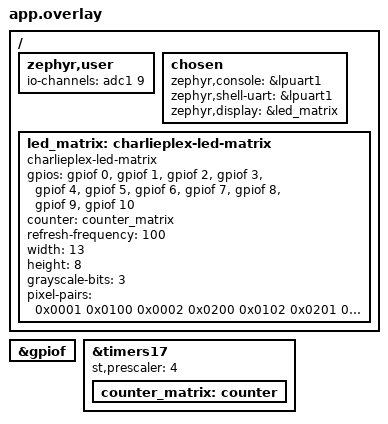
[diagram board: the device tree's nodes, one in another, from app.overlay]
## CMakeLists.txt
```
# Copyright (c) 2026 Eoin Jordan
# SPDX-License-Identifier: Apache-2.0
#
# ExecuTorch anomaly classifier on the Arduino UNO Q's STM32U585 (Cortex-M33)
# under Zephyr. Same structure as the upstream zephyr/samples/hello-executorch
# sample: model embedded as a const array, only the operators in the .pte are
# linked.

cmake_minimum_required(VERSION 3.24)

set(CMAKE_SKIP_INSTALL_RULES ON CACHE BOOL "" FORCE)

set(ET_PTE_FILE_PATH
    "${CMAKE_CURRENT_SOURCE_DIR}/model/anomaly_net.pte"
    CACHE FILEPATH "Path to the ExecuTorch .pte model to embed"
)
if(NOT IS_ABSOLUTE "${ET_PTE_FILE_PATH}")
  get_filename_component(
    ET_PTE_FILE_PATH "${ET_PTE_FILE_PATH}" ABSOLUTE BASE_DIR
    "${CMAKE_CURRENT_SOURCE_DIR}"
  )
endif()
if(NOT EXISTS "${ET_PTE_FILE_PATH}")
  message(FATAL_ERROR "Model not found at ET_PTE_FILE_PATH=${ET_PTE_FILE_PATH}. "
                      "Run train/train_anomaly.py first or pass -DET_PTE_FILE_PATH=<file>.")
endif()

# Bindings for the vendored LED matrix driver (dts/bindings/).
list(APPEND DTS_ROOT ${CMAKE_CURRENT_SOURCE_DIR})

find_package(Zephyr REQUIRED HINTS $ENV{ZEPHYR_BASE})
project(executorch_arduino_uno_q)

find_package(Python3 COMPONENTS Interpreter REQUIRED)

set(CMAKE_CXX_FLAGS
    "${CMAKE_CXX_FLAGS} -Wall -Wno-switch -Wno-float-conversion -ffunction-sections -fdata-sections"
)

if(NOT DEFINED EXECUTORCH_DIR)
  if(DEFINED ZEPHYR_EXECUTORCH_MODULE_DIR)
    set(EXECUTORCH_DIR ${ZEPHYR_EXECUTORCH_MODULE_DIR})
  else()
    message(FATAL_ERROR "ExecuTorch Zephyr module not found. Check west.yml and run west update.")
  endif()
endif()
message(STATUS "EXECUTORCH_DIR=${EXECUTORCH_DIR}")

include(${EXECUTORCH_DIR}/tools/cmake/Utils.cmake)
include(${EXECUTORCH_DIR}/backends/arm/cmake/ArmRunnerUtils.cmake)

if(NOT TARGET portable_kernels)
  set(EXECUTORCH_PORTABLE_BUILD_KERNELS_ONLY ON)
  add_subdirectory(
    ${EXECUTORCH_DIR}/kernels/portable
    ${CMAKE_CURRENT_BINARY_DIR}/executorch/kernels/portable
  )
  unset(EXECUTORCH_PORTABLE_BUILD_KERNELS_ONLY)
endif()

set(_selected_ops_libs)

arm_runner_create_selected_ops_lib(
  LIB_NAME "unoq_portable_ops_lib"
  FUNCTIONS_YAML "${EXECUTORCH_DIR}/kernels/portable/functions.yaml"
  OPS_FROM_MODEL "${ET_PTE_FILE_PATH}"
  KERNEL_LIBS portable_kernels
  DEPS executorch
  DTYPE_SELECTIVE_BUILD ""
)
list(APPEND _selected_ops_libs unoq_portable_ops_lib)

if(TARGET cortex_m_kernels)
  arm_runner_create_selected_ops_lib(
    LIB_NAME "unoq_cortex_m_ops_lib"
    CUSTOM_OPS_YAML "${EXECUTORCH_DIR}/backends/cortex_m/ops/operators.yaml"
    OPS_FROM_MODEL "${ET_PTE_FILE_PATH}"
    KERNEL_LIBS cortex_m_kernels
    DEPS executorch
  )
  list(APPEND _selected_ops_libs unoq_cortex_m_ops_lib)
endif()

set(_local_flatcc_root ${CMAKE_BINARY_DIR}/flatcc_src)
if(NOT EXISTS ${_local_flatcc_root}/CMakeLists.txt)
  file(MAKE_DIRECTORY ${_local_flatcc_root})
  execute_process(
    COMMAND ${CMAKE_COMMAND} -E copy_directory
            ${EXECUTORCH_DIR}/third-party/flatcc ${_local_flatcc_root}
  )
endif()
set(EXECUTORCH_FLATCC_SOURCE_ROOT ${_local_flatcc_root} CACHE PATH "" FORCE)
set(EXECUTORCH_FLATCC_INSTALL_ROOT ${_local_flatcc_root} CACHE PATH "" FORCE)

set(_model_pte_header ${CMAKE_CURRENT_BINARY_DIR}/model_pte.h)
add_custom_command(
  OUTPUT ${_model_pte_header}
  COMMAND ${Python3_EXECUTABLE} ${CMAKE_CURRENT_SOURCE_DIR}/scripts/pte_to_header.py
          --pte ${ET_PTE_FILE_PATH} --out ${_model_pte_header}
  DEPENDS ${ET_PTE_FILE_PATH} ${CMAKE_CURRENT_SOURCE_DIR}/scripts/pte_to_header.py
  COMMENT "Converting ${ET_PTE_FILE_PATH} to model_pte.h"
)
add_custom_target(gen_model_header DEPENDS ${_model_pte_header})
add_dependencies(app gen_model_header)

# The ExecuTorch module's runtime includes <zephyr/kernel.h>, which needs
# Zephyr's generated headers. Order it explicitly so a parallel build does not
# compile it before they exist.
if(TARGET zephyr_generated_headers)
  foreach(_t executorch_core executorch portable_kernels kernels_util_all_deps cortex_m_kernels)
    if(TARGET ${_t})
      add_dependencies(${_t} zephyr_generated_headers)
    endif()
  endforeach()
endif()

target_sources(app PRIVATE src/main.cpp src/sensor.c)

if(CONFIG_APP_LED_MATRIX)
  target_sources(app PRIVATE src/matrix.c drivers/display_charlieplex_led_matrix.c)
endif()

target_compile_definitions(
  app PRIVATE
  APP_METHOD_ALLOCATOR_POOL_SIZE=${CONFIG_EXECUTORCH_METHOD_ALLOCATOR_POOL_SIZE}
  APP_TEMP_ALLOCATOR_POOL_SIZE=${CONFIG_EXECUTORCH_TEMP_ALLOCATOR_POOL_SIZE}
)

target_link_libraries(app PRIVATE libexecutorch ${_selected_ops_libs})
target_include_directories(app PRIVATE src ${CMAKE_CURRENT_BINARY_DIR})
```

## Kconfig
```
# Copyright (c) 2026 Eoin Jordan
# SPDX-License-Identifier: Apache-2.0

source "Kconfig.zephyr"

menu "ExecuTorch Arduino UNO Q anomaly sample"

config EXECUTORCH_METHOD_ALLOCATOR_POOL_SIZE
	int "Method allocator pool size in bytes"
	default 65536
	depends on EXECUTORCH

config EXECUTORCH_TEMP_ALLOCATOR_POOL_SIZE
	int "Temporary allocator pool size in bytes"
	default 8192
	depends on EXECUTORCH

config APP_SIM_SENSOR
	bool "Simulate the temperature sensor instead of reading A0"
	default y
	help
	  Generates a normal heater cycle in software and injects a spike
	  every 30 s so the Linux side sees both classes. Set to n once a
	  sensor is wired to A0.

config APP_SAMPLE_PERIOD_MS
	int "Sensor sample period in milliseconds"
	default 100
	help
	  Must match SAMPLE_HZ in train/model.py (10 Hz).

config APP_INFER_PERIOD_MS
	int "Inference period in milliseconds"
	default 500

config APP_MV_PER_DEGREE
	int "Sensor scale: millivolts per degree C (x10)"
	default 100
	help
	  Tenths of a millivolt per degree. Default 100 = 10.0 mV/C (TMP36).

config APP_MV_OFFSET
	int "Sensor offset: millivolts at 0 C"
	default 500
	help
	  TMP36 outputs 500 mV at 0 C.

config APP_ANOMALY_THRESHOLD_PERCENT
	int "Anomaly probability (percent) that lights the red LED"
	default 80

endmenu

config APP_LED_MATRIX
	bool "Show the anomaly probability on the 13x8 LED matrix"
	default y
	select GPIO
	select COUNTER
	select DISPLAY
	help
	  Rolling bar chart on the UNO Q's charlieplexed LED matrix: one column
	  per inference, height = p(anomaly), bright when the MCU flagged an
	  anomaly, dotted when the sensor reads out of range. The matrix driver
	  lives in firmware/drivers/ and is wired up in app.overlay.
```

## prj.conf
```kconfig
# Copyright (c) 2026 Eoin Jordan
# SPDX-License-Identifier: Apache-2.0

# ExecuTorch runtime, selective operator build
CONFIG_EXECUTORCH=y
CONFIG_EXECUTORCH_BUILD_PORTABLE_OPS=n
CONFIG_EXECUTORCH_ENABLE_LOGGING=y

# C++17 with full libstdc++
CONFIG_CPP=y
CONFIG_STD_CPP17=y

CONFIG_MAIN_STACK_SIZE=16384
CONFIG_HEAP_MEM_POOL_SIZE=32768

# Cortex-M33 FPU, hard-float ABI
CONFIG_FPU=y
CONFIG_FP_HARDABI=y

CONFIG_REQUIRES_FLOAT_PRINTF=y
CONFIG_PRINTK=y

# A0 on ADC1, RGB LEDs on GPIO
CONFIG_GPIO=y
CONFIG_ADC=y

CONFIG_EXECUTORCH_METHOD_ALLOCATOR_POOL_SIZE=65536
CONFIG_EXECUTORCH_TEMP_ALLOCATOR_POOL_SIZE=8192
```

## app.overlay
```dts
/* Copyright (c) 2026 Eoin Jordan
 * SPDX-License-Identifier: Apache-2.0
 *
 * A0 on the UNO Q header is PA4 = ADC1 channel 9 (14-bit, 3.3 V reference).
 * Expose it to the application as io-channels index 0.
 */

/ {
	zephyr,user {
		io-channels = <&adc1 9>;
	};
};

/* The board file puts the console on USART1, which is the header serial
 * (D0/D1). The UART that links the STM32 to the QRB2210 is LPUART1
 * (/dev/ttyHS1 on the Linux side), so send the console and the JSON stream
 * there instead.
 */
/ {
	chosen {
		zephyr,console = &lpuart1;
		zephyr,shell-uart = &lpuart1;
	};
};

/* 13x8 LED matrix: 11 charlieplexed lines on PF0..PF10, scanned from TIM17.
 * Node copied from upstream Zephyr main (boards/arduino/uno_q); the matching
 * driver is vendored in drivers/ until the manifest moves past v4.4.0.
 * pixel-pairs is row-major (index = y * 13 + x), entry = (high << 8) | low.
 */
/ {
	chosen {
		zephyr,display = &led_matrix;
	};

	led_matrix: charlieplex-led-matrix {
		compatible = "charlieplex-led-matrix";
		gpios = <&gpiof 0 0>, <&gpiof 1 0>, <&gpiof 2 0>,
			<&gpiof 3 0>, <&gpiof 4 0>, <&gpiof 5 0>,
			<&gpiof 6 0>, <&gpiof 7 0>, <&gpiof 8 0>,
			<&gpiof 9 0>, <&gpiof 10 0>;
		counter = <&counter_matrix>;
		refresh-frequency = <100>;
		width = <13>;
		height = <8>;
		grayscale-bits = <3>;
		pixel-pairs = <0x0001 0x0100 0x0002 0x0200 0x0102 0x0201 0x0003 0x0300 0x0103 0x0301
			       0x0203 0x0302 0x0004 0x0400 0x0104 0x0401 0x0204 0x0402 0x0304 0x0403
			       0x0005 0x0500 0x0105 0x0501 0x0205 0x0502 0x0305 0x0503 0x0405 0x0504
			       0x0006 0x0600 0x0106 0x0601 0x0206 0x0602 0x0306 0x0603 0x0406 0x0604
			       0x0506 0x0605 0x0007 0x0700 0x0107 0x0701 0x0207 0x0702 0x0307 0x0703
			       0x0407 0x0704 0x0507 0x0705 0x0607 0x0706 0x0008 0x0800 0x0108 0x0801
			       0x0208 0x0802 0x0308 0x0803 0x0408 0x0804 0x0508 0x0805 0x0608 0x0806
			       0x0708 0x0807 0x0009 0x0900 0x0109 0x0901 0x0209 0x0902 0x0309 0x0903
			       0x0409 0x0904 0x0509 0x0905 0x0609 0x0906 0x0709 0x0907 0x0809 0x0908
			       0x000a 0x0a00 0x010a 0x0a01 0x020a 0x0a02 0x030a 0x0a03 0x040a 0x0a04
			       0x050a 0x0a05 0x060a 0x0a06>;
	};
};

&gpiof {
	status = "okay";
};

&timers17 {
	status = "okay";
	st,prescaler = <4>;

	counter_matrix: counter {
		status = "okay";
	};
};
```

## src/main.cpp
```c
/* Copyright (c) 2026 Eoin Jordan
 * SPDX-License-Identifier: Apache-2.0
 *
 * MCU brain of the Arduino UNO Q dual-brain sample.
 *
 *   A0 (or simulated) --10 Hz--> ring buffer of 32 samples
 *        --every 500 ms--> ExecuTorch AnomalyNet --> one JSON line on the UART
 *                                               --> RGB LED 3 green / red
 *
 * The Linux brain (QRB2210) reads the JSON lines; see linux/anomaly_bridge.py.
 */

#include <executorch/extension/data_loader/buffer_data_loader.h>
#include <executorch/runtime/core/memory_allocator.h>
#include <executorch/runtime/core/span.h>
#include <executorch/runtime/executor/memory_manager.h>
#include <executorch/runtime/executor/method.h>
#include <executorch/runtime/executor/program.h>
#include <executorch/runtime/platform/log.h>
#include <executorch/runtime/platform/runtime.h>

#include <zephyr/drivers/gpio.h>
#include <zephyr/kernel.h>
#include <zephyr/sys/printk.h>
#include <zephyr/version.h>

#include <cmath>
#include <cstdint>
#include <cstring>
#include <vector>

#include "model_pte.h"
#include "sensor.h"
#include "matrix.h"
#include "test_input.h"

using executorch::aten::Tensor;
using executorch::aten::TensorImpl;
using executorch::extension::BufferDataLoader;
using executorch::runtime::Error;
using executorch::runtime::EValue;
using executorch::runtime::HierarchicalAllocator;
using executorch::runtime::MemoryAllocator;
using executorch::runtime::MemoryManager;
using executorch::runtime::Method;
using executorch::runtime::MethodMeta;
using executorch::runtime::Program;
using executorch::runtime::Result;
using executorch::runtime::Span;
using executorch::runtime::TensorInfo;

static constexpr float kMean = 50.0f;
static constexpr float kScale = 20.0f;
static constexpr size_t kWindow = TEST_WINDOW;
static constexpr size_t kNumClasses = TEST_NUM_CLASSES;
static constexpr float kThreshold = CONFIG_APP_ANOMALY_THRESHOLD_PERCENT / 100.0f;

#ifndef APP_METHOD_ALLOCATOR_POOL_SIZE
#define APP_METHOD_ALLOCATOR_POOL_SIZE (64 * 1024)
#endif
#ifndef APP_TEMP_ALLOCATOR_POOL_SIZE
#define APP_TEMP_ALLOCATOR_POOL_SIZE (8 * 1024)
#endif

alignas(16) static uint8_t method_pool[APP_METHOD_ALLOCATOR_POOL_SIZE];
alignas(16) static uint8_t temp_pool[APP_TEMP_ALLOCATOR_POOL_SIZE];

/* RGB LED 3 on the UNO Q (active low in devicetree, handled by the GPIO flags) */
static const struct gpio_dt_spec led_green = GPIO_DT_SPEC_GET(DT_NODELABEL(led3_green), gpios);
static const struct gpio_dt_spec led_red = GPIO_DT_SPEC_GET(DT_NODELABEL(led3_red), gpios);

namespace {

struct Runner {
	BufferDataLoader loader{model_pte, model_pte_len};
	MemoryAllocator method_allocator{APP_METHOD_ALLOCATOR_POOL_SIZE, method_pool};
	MemoryAllocator temp_allocator{APP_TEMP_ALLOCATOR_POOL_SIZE, temp_pool};
	std::vector<Span<uint8_t>> planned_spans;
	Program *program = nullptr;
	Method *method = nullptr;
	float *input = nullptr;
	size_t input_numel = 0;
	Tensor *input_tensor = nullptr;

	Error init();
	Error run(const float *window, float *logits, uint32_t *us);
};

Error Runner::init()
{
	Result<Program> program_res = Program::load(&loader);
	if (!program_res.ok()) {
		ET_LOG(Error, "Program::load failed: 0x%x", (unsigned)program_res.error());
		return program_res.error();
	}
	program = new Program(std::move(program_res.get()));

	const char *method_name = program->get_method_name(0).get();
	Result<MethodMeta> meta = program->method_meta(method_name);
	if (!meta.ok()) {
		return meta.error();
	}

	for (size_t id = 0; id < meta->num_memory_planned_buffers(); ++id) {
		size_t size = static_cast<size_t>(meta->memory_planned_buffer_size(id).get());
		uint8_t *buf = static_cast<uint8_t *>(method_allocator.allocate(size, 16));
		if (buf == nullptr) {
			ET_LOG(Error, "planned buffer %zu (%zu B) does not fit the method pool", id, size);
			return Error::MemoryAllocationFailed;
		}
		ET_LOG(Info, "planned buffer %zu: %zu bytes", id, size);
		planned_spans.push_back({buf, size});
	}

	static HierarchicalAllocator planned_memory({planned_spans.data(), planned_spans.size()});
	static MemoryManager memory_manager(&method_allocator, &planned_memory, &temp_allocator);

	Result<Method> method_res = program->load_method(method_name, &memory_manager);
	if (!method_res.ok()) {
		ET_LOG(Error, "load_method(%s) failed: 0x%x", method_name, (unsigned)method_res.error());
		return method_res.error();
	}
	method = new Method(std::move(method_res.get()));

	Result<TensorInfo> in_meta = meta->input_tensor_meta(0);
	if (!in_meta.ok()) {
		return in_meta.error();
	}
	input_numel = in_meta->nbytes() / sizeof(float);
	input = static_cast<float *>(method_allocator.allocate(in_meta->nbytes(), 16));
	if (input == nullptr) {
		return Error::MemoryAllocationFailed;
	}
	static TensorImpl impl(
		in_meta->scalar_type(), in_meta->sizes().size(),
		const_cast<TensorImpl::SizesType *>(in_meta->sizes().data()), input,
		const_cast<TensorImpl::DimOrderType *>(in_meta->dim_order().data()));
	static Tensor tensor(&impl);
	input_tensor = &tensor;

	ET_LOG(Info, "method '%s' loaded; input numel %zu; pool used %zu / %zu bytes", method_name,
	       input_numel, method_allocator.used_size(), method_allocator.size());
	return Error::Ok;
}

Error Runner::run(const float *window, float *logits, uint32_t *us)
{
	std::memcpy(input, window, input_numel * sizeof(float));
	Error err = method->set_input(EValue(*input_tensor), 0);
	if (err != Error::Ok) {
		return err;
	}
	uint32_t t0 = k_cycle_get_32();
	err = method->execute();
	uint32_t t1 = k_cycle_get_32();
	if (err != Error::Ok) {
		ET_LOG(Error, "execute failed: 0x%x", (unsigned)err);
		return err;
	}
	*us = k_cyc_to_us_floor32(t1 - t0);

	const EValue &out = method->get_output(0);
	if (!out.isTensor()) {
		return Error::InvalidState;
	}
	const float *data = out.toTensor().const_data_ptr<float>();
	for (size_t i = 0; i < kNumClasses; ++i) {
		logits[i] = data[i];
	}
	return Error::Ok;
}

float anomaly_probability(const float *logits)
{
	float m = fmaxf(logits[0], logits[1]);
	float e0 = expf(logits[0] - m), e1 = expf(logits[1] - m);
	return e1 / (e0 + e1);
}

bool self_test(Runner &runner, const char *name, const float *window, const float *expected,
	       size_t expect_cls)
{
	float logits[kNumClasses];
	uint32_t us = 0;
	if (runner.run(window, logits, &us) != Error::Ok) {
		printk("  %s: inference failed\n", name);
		return false;
	}
	float diff = 0.f;
	size_t pred = logits[1] > logits[0] ? 1 : 0;
	for (size_t i = 0; i < kNumClasses; ++i) {
		diff = fmaxf(diff, fabsf(logits[i] - expected[i]));
	}
	printk("  %s: logits [%.4f %.4f] p(anomaly)=%.3f pred=%zu expected=%zu max|m33-pytorch|=%.1e (%u us)\n",
	       name, (double)logits[0], (double)logits[1], (double)anomaly_probability(logits), pred,
	       expect_cls, (double)diff, us);
	return pred == expect_cls && diff < 1e-3f;
}

} // namespace

int main(void)
{
	executorch::runtime::runtime_init();

	printk("\nExecuTorch on %s (Zephyr %s)\n", CONFIG_BOARD_TARGET, KERNEL_VERSION_STRING);
	printk("model: %u bytes in flash, method pool %u B, temp pool %u B\n",
	       (unsigned)model_pte_len, (unsigned)APP_METHOD_ALLOCATOR_POOL_SIZE,
	       (unsigned)APP_TEMP_ALLOCATOR_POOL_SIZE);

	if (gpio_is_ready_dt(&led_green) && gpio_is_ready_dt(&led_red)) {
		gpio_pin_configure_dt(&led_green, GPIO_OUTPUT_INACTIVE);
		gpio_pin_configure_dt(&led_red, GPIO_OUTPUT_INACTIVE);
	}

	if (matrix_init() == 0) {
		printk("matrix: 13x8 LED matrix on PF0..PF10, rolling p(anomaly) chart\n");
	}

	static Runner runner;
	if (runner.init() != Error::Ok) {
		printk("FAIL: runtime init\n");
		return 1;
	}

	printk("\nself-test:\n");
	bool ok = self_test(runner, "normal ", kTestNormal, kTestNormalLogits, 0);
	ok &= self_test(runner, "anomaly", kTestAnomaly, kTestAnomalyLogits, 1);
	printk(ok ? "SELF-TEST PASS\n" : "SELF-TEST FAIL\n");
	matrix_show_selftest(ok);

	if (sensor_init() != 0) {
		printk("FAIL: sensor init\n");
		return 1;
	}

	static float ring[kWindow];
	size_t head = 0, filled = 0;
	float logits[kNumClasses];
	uint32_t us = 0, seq = 0;
	int64_t next_infer = k_uptime_get() + CONFIG_APP_INFER_PERIOD_MS;

	for (;;) {
		float c;
		bool in_range = sensor_read_celsius(&c);
		ring[head] = (c - kMean) / kScale;
		head = (head + 1) % kWindow;
		if (filled < kWindow) {
			filled++;
		}

		if (filled == kWindow && k_uptime_get() >= next_infer) {
			next_infer += CONFIG_APP_INFER_PERIOD_MS;
			float window[kWindow];
			for (size_t i = 0; i < kWindow; ++i) {
				window[i] = ring[(head + i) % kWindow];
			}
			if (runner.run(window, logits, &us) == Error::Ok) {
				float p = anomaly_probability(logits);
				bool anomaly = p >= kThreshold || !in_range;
				gpio_pin_set_dt(&led_green, !anomaly);
				gpio_pin_set_dt(&led_red, anomaly);
				matrix_push(p, anomaly, in_range);
				/* One JSON object per line: the contract with the Linux side. */
				printk("{\"seq\":%u,\"t_ms\":%lld,\"temp_c\":%.2f,\"p_anomaly\":%.3f,"
				       "\"anomaly\":%d,\"sensor_ok\":%d,\"infer_us\":%u}\n",
				       seq++, (long long)k_uptime_get(), (double)c, (double)p, anomaly,
				       in_range, us);
			}
		}
		k_msleep(CONFIG_APP_SAMPLE_PERIOD_MS);
	}
	return 0;
}
```

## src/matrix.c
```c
/* Copyright (c) 2026 Eoin Jordan
 * SPDX-License-Identifier: Apache-2.0
 *
 * Rolling anomaly-probability chart on the UNO Q's 13x8 charlieplexed LED
 * matrix, through Zephyr's display API. The driver exposes a framebuffer of
 * one byte per pixel, row-major, 0 .. (2^grayscale-bits - 1).
 *
 *   x = 0 is the oldest inference, x = 12 the newest.
 *   column height  = p(anomaly) scaled to the 8 rows (at least one pixel so
 *                    a healthy loop still shows a heartbeat)
 *   dim column     = normal
 *   bright column  = the MCU flagged an anomaly
 *   dotted column  = the sensor read out of range (open or shorted input)
 */

#include "matrix.h"

#include <math.h>
#include <string.h>

#include <zephyr/device.h>
#include <zephyr/devicetree.h>
#include <zephyr/drivers/display.h>
#include <zephyr/kernel.h>

#define MATRIX_NODE DT_CHOSEN(zephyr_display)
#define LEVELS      (1u << DT_PROP(MATRIX_NODE, grayscale_bits))
#define BRIGHT      (uint8_t)(LEVELS - 1)
#define DIM         (uint8_t)(LEVELS / 4 > 0 ? LEVELS / 4 : 1)

static const struct device *const matrix = DEVICE_DT_GET(MATRIX_NODE);
static uint8_t *fb;
static uint16_t width, height;
static bool showing_selftest;

static void set(uint16_t x, uint16_t y, uint8_t v)
{
	if (x < width && y < height) {
		fb[y * width + x] = v;
	}
}

int matrix_init(void)
{
	if (!device_is_ready(matrix)) {
		return -ENODEV;
	}

	struct display_capabilities caps;
	display_get_capabilities(matrix, &caps);
	width = caps.x_resolution;
	height = caps.y_resolution;

	fb = display_get_framebuffer(matrix);
	if (fb == NULL || width == 0 || height == 0) {
		return -ENOTSUP;
	}
	memset(fb, 0, (size_t)width * height);
	display_blanking_off(matrix);
	return 0;
}

void matrix_show_selftest(bool ok)
{
	if (fb == NULL) {
		return;
	}
	memset(fb, 0, (size_t)width * height);
	if (ok) {
		/* Tick: short stroke down from (2,4), long stroke up to (11,1). */
		for (int i = 0; i < 3; i++) {
			set(2 + i, 4 + i, BRIGHT);
		}
		for (int i = 0; i < 7; i++) {
			set(5 + i, 7 - i, BRIGHT);
		}
	} else {
		/* Cross over the middle 8 columns. */
		for (int i = 0; i < 8; i++) {
			set(2 + i, i, BRIGHT);
			set(9 - i, i, BRIGHT);
		}
	}
	showing_selftest = true;
}

void matrix_push(float p_anomaly, bool anomaly, bool sensor_ok)
{
	if (fb == NULL) {
		return;
	}
	if (showing_selftest) {
		memset(fb, 0, (size_t)width * height);
		showing_selftest = false;
	} else {
		for (uint16_t y = 0; y < height; y++) {
			memmove(&fb[y * width], &fb[y * width + 1], width - 1);
		}
	}

	if (p_anomaly < 0.f) {
		p_anomaly = 0.f;
	} else if (p_anomaly > 1.f) {
		p_anomaly = 1.f;
	}
	int bar = (int)lroundf(p_anomaly * height);
	if (bar < 1) {
		bar = 1;
	}

	const uint16_t x = width - 1;
	const uint8_t level = anomaly ? BRIGHT : DIM;
	for (uint16_t y = 0; y < height; y++) {
		bool lit = (int)y >= (int)height - bar;
		if (!sensor_ok) {
			lit = (y & 1u) == 0u;
		}
		set(x, y, lit ? level : 0);
	}
}
```

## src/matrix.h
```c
/* Copyright (c) 2026 Eoin Jordan
 * SPDX-License-Identifier: Apache-2.0
 *
 * Inference results on the UNO Q's 13x8 LED matrix. No-ops when the matrix
 * is compiled out (CONFIG_APP_LED_MATRIX=n).
 */
#pragma once

#include <errno.h>
#include <stdbool.h>

#ifdef __cplusplus
extern "C" {
#endif

#ifdef CONFIG_APP_LED_MATRIX

/* Returns 0 when the matrix is ready, -ENODEV/-ENOTSUP otherwise. */
int matrix_init(void);

/* Tick for pass, cross for fail. Stays until the first matrix_push(). */
void matrix_show_selftest(bool ok);

/* Scroll the chart left and add one column: height = p_anomaly, bright when
 * the MCU flagged an anomaly, dotted when the sensor read out of range. */
void matrix_push(float p_anomaly, bool anomaly, bool sensor_ok);

#else

static inline int matrix_init(void)
{
	return -ENODEV;
}
static inline void matrix_show_selftest(bool ok)
{
	(void)ok;
}
static inline void matrix_push(float p_anomaly, bool anomaly, bool sensor_ok)
{
	(void)p_anomaly;
	(void)anomaly;
	(void)sensor_ok;
}

#endif /* CONFIG_APP_LED_MATRIX */

#ifdef __cplusplus
}
#endif
```

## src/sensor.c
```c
/* Copyright (c) 2026 Eoin Jordan
 * SPDX-License-Identifier: Apache-2.0
 *
 * Analog temperature sensor on A0 (TMP36 by default), or a software
 * simulation of the same signal when CONFIG_APP_SIM_SENSOR=y.
 */

#include "sensor.h"

#include <math.h>
#include <zephyr/kernel.h>
#include <zephyr/sys/printk.h>

#ifdef CONFIG_APP_SIM_SENSOR

static float sim_t;          /* seconds */
static uint32_t lcg = 12345; /* tiny PRNG for sensor noise */

static float noise(void)
{
	lcg = lcg * 1664525u + 1013904223u;
	return ((float)(lcg >> 8) / 16777216.0f - 0.5f) * 0.6f; /* +-0.3 C */
}

int sensor_init(void)
{
	printk("sensor: simulated heater loop (CONFIG_APP_SIM_SENSOR=y); spike every 30 s\n");
	return 0;
}

bool sensor_read_celsius(float *celsius)
{
	float c = 50.0f + 4.0f * sinf(2.0f * 3.14159265f * sim_t / 60.0f) + noise();
	/* three-sample spike once every 30 s */
	float phase = fmodf(sim_t, 30.0f);

	if (phase >= 25.0f && phase < 25.3f) {
		c += 18.0f;
	}
	sim_t += CONFIG_APP_SAMPLE_PERIOD_MS / 1000.0f;
	*celsius = c;
	return true;
}

#else /* real ADC */

#include <zephyr/drivers/adc.h>

static const struct adc_dt_spec adc = ADC_DT_SPEC_GET_BY_IDX(DT_PATH(zephyr_user), 0);
static uint16_t sample;
static struct adc_sequence seq = {
	.buffer = &sample,
	.buffer_size = sizeof(sample),
};

int sensor_init(void)
{
	int ret;

	if (!adc_is_ready_dt(&adc)) {
		printk("sensor: ADC %s not ready\n", adc.dev->name);
		return -ENODEV;
	}
	ret = adc_channel_setup_dt(&adc);
	if (ret < 0) {
		return ret;
	}
	ret = adc_sequence_init_dt(&adc, &seq);
	if (ret < 0) {
		return ret;
	}
	printk("sensor: %s channel %u, %d.%d mV/C, %d mV at 0 C\n", adc.dev->name, adc.channel_id,
	       CONFIG_APP_MV_PER_DEGREE / 10, CONFIG_APP_MV_PER_DEGREE % 10, CONFIG_APP_MV_OFFSET);
	return 0;
}

bool sensor_read_celsius(float *celsius)
{
	int ret = adc_read_dt(&adc, &seq);

	if (ret < 0) {
		printk("sensor: adc_read %d\n", ret);
		*celsius = 0.0f;
		return false;
	}
	int32_t mv = sample;

	ret = adc_raw_to_millivolts_dt(&adc, &mv);
	if (ret < 0) {
		*celsius = 0.0f;
		return false;
	}
	*celsius = (float)(mv - CONFIG_APP_MV_OFFSET) * 10.0f / (float)CONFIG_APP_MV_PER_DEGREE;
	return mv > 20 && mv < 3280;
}

#endif
```

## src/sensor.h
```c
/* Copyright (c) 2026 Eoin Jordan
 * SPDX-License-Identifier: Apache-2.0
 */
#pragma once

#include <stdbool.h>

#ifdef __cplusplus
extern "C" {
#endif

int sensor_init(void);

/* One temperature reading in degrees C. Returns false if the input is out of
 * range (open or shorted). */
bool sensor_read_celsius(float *celsius);

#ifdef __cplusplus
}
#endif
```

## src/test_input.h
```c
/* Generated by train/train_anomaly.py. Do not edit. */
#pragma once

#define TEST_WINDOW 32
#define TEST_NUM_CLASSES 2

/* Windows are already normalised with (t - MEAN) / SCALE. */
static const float kTestNormal[32] = {
    0.264098f, 0.249371f, 0.271595f, 0.263522f, 0.257505f, 0.247585f, 0.253729f, 0.254576f,
    0.258493f, 0.265816f, 0.265668f, 0.293701f, 0.271193f, 0.274132f, 0.257883f, 0.265960f,
    0.275539f, 0.267300f, 0.276547f, 0.266455f, 0.252052f, 0.273292f, 0.266936f, 0.277063f,
    0.224938f, 0.236032f, 0.257732f, 0.246616f, 0.242959f, 0.251983f, 0.240990f, 0.256992f,
};
static const float kTestNormalLogits[2] = {
    2.883032f, -1.948895f,
};
static const float kTestAnomaly[32] = {
    0.264098f, 0.249371f, 0.271595f, 0.263522f, 0.257505f, 0.247585f, 0.253729f, 0.254576f,
    0.258493f, 0.265816f, 0.265668f, 0.293701f, 1.171193f, 1.174132f, 1.157883f, 0.265960f,
    0.275539f, 0.267300f, 0.276547f, 0.266455f, 0.252052f, 0.273292f, 0.266936f, 0.277063f,
    0.224938f, 0.236032f, 0.257732f, 0.246616f, 0.242959f, 0.251983f, 0.240990f, 0.256992f,
};
static const float kTestAnomalyLogits[2] = {
    -12.694772f, 12.602264f,
};
```
